# ESP32-C61 register map
Vendor: ESPRESSIF SYSTEMS (SHANGHAI) CO., LTD.; Series: ESP32 C-Series; File version: 1
CPU: RV32IMAC r0p0, little endian, no MPU, no FPU, 0 interrupt priority bits
Address unit: 32 bits
Registers are 32-bit, read-write, reset 0x0 unless marked. A register's access mark holds for its fields unless they carry their own. Offsets are from the block's base; [hi:lo] are bit positions; {n}, {i} and the like mark numbered series.

## INTERRUPT_CORE0 — Interrupt Controller (Core 0)
Base 0x60010000
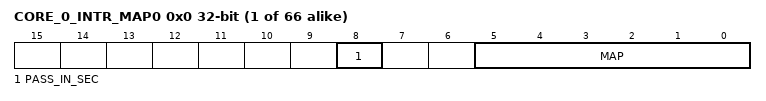
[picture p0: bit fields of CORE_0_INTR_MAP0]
{0x0+4i} CORE_0_INTR_MAP{i} (i=0..65)
  [8] PASS_IN_SEC, [5:0] MAP
{0x108+4i} CORE_0_INTR_STATUS{i} (i=0..2) ro — Represents the status of the interrupt sources. Each bit corresponds to one interrupt source
  [31:0] INT_STATUS_0 — Represents the status of the interrupt sources within interrupt-index-range 0 ~ 31. Each bit corresponds to one interrupt source 0:The corresponding interrupt source triggered an interrupt 1:No interrupt triggered
0x114 SRC_PASS_IN_SEC_STATUS_0 ro — PASS_IN_SEC status register for interrupt sources 0 ~ 31
  [31:0] INT_SRC_PASS_IN_SEC_STATUS_0 — Represents the PASS_IN_SEC status of the interrupt sources within interrupt-index-range 0 ~ 31. Each bit corresponds to one interrupt source 0:The corresponding interrupt source is not PASS_IN_SEC. 1:The corresponding interrupt source is PASS_IN_SEC.
0x118 SRC_PASS_IN_SEC_STATUS_1 ro — PASS_IN_SEC status register for interrupt sources 32 ~ 63
  [31:0] INT_SRC_PASS_IN_SEC_STATUS_1 — Represents the PASS_IN_SEC status of the interrupt sources within interrupt-index-range 32 ~ 63. Each bit corresponds to one interrupt source 0:The corresponding interrupt source is not PASS_IN_SEC. 1:The corresponding interrupt source is PASS_IN_SEC.
0x11C SRC_PASS_IN_SEC_STATUS_2 ro — PASS_IN_SEC status register for interrupt sources 64 ~ 65
  [1:0] INT_SRC_PASS_IN_SEC_STATUS_2 — Represents the PASS_IN_SEC status of the interrupt sources with interrupt-index-range 64 ~ 65. Each bit corresponds to one interrupt source 0:The corresponding interrupt source is not PASS_IN_SEC. 1:The corresponding interrupt source is PASS_IN_SEC.
0x120 SIG_IDX_ASSERT_IN_SEC — reserved
  [5:0] INT_SIG_IDX_ASSERT_IN_SEC
0x124 SECURE_STATUS ro — reserved
  [31:0] INT_SECURE_STATUS
0x128 CLOCK_GATE — Interrupt clock gating configure register
  [0] REG_CLK_EN
0x7FC INTERRUPT_DATE — Version control register

## INTPRI — INTPRI Peripheral
Base 0x600C5000
{0x90+4i} CPU_INTR_FROM_CPU{i} (i=0..3) — CPU_INTR_FROM_CPU{i} mapping register
  [0] CPU_INTR — CPU_INTR_FROM_CPU_%s mapping register.
0xA0 DATE — Version control register
0xA4 CLOCK_GATE reset 0x1 — register description
  [0] CLK_EN — Need add description
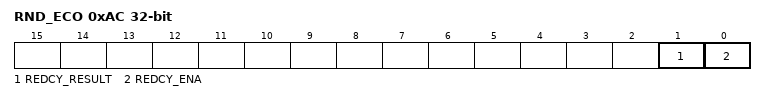
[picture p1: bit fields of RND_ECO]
0xAC RND_ECO access per field — redcy eco register.
  [1] REDCY_RESULT ro — Only reserved for ECO.
  [0] REDCY_ENA rw — Only reserved for ECO.
0xB0 RND_ECO_LOW — redcy eco low register.
  [31:0] REDCY_LOW — Only reserved for ECO.
0x3FC RND_ECO_HIGH reset 0xFFFFFFFF — redcy eco high register.
  [31:0] REDCY_HIGH — Only reserved for ECO.

## IO_MUX — Input/Output Multiplexer
Base 0x60090000
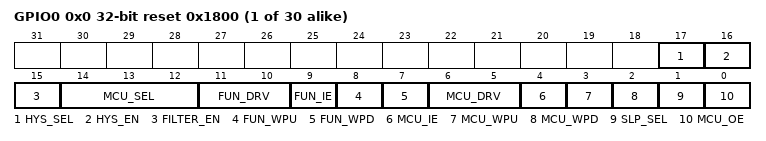
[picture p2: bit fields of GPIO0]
{0x0+4i} GPIO{i} (i=0..29) reset 0x1800 — IO_MUX Configure Registers for different pads
  [17] HYS_SEL — Select enabling signals of the pad from software and efuse hardware. 1: Select enabling siganl from slftware. 0: Select enabling signal from efuse hardware.
  [16] HYS_EN — Software enables hysteresis function for the pad. 1: Hysteresis enabled. 0: Hysteresis disabled.
  [15] FILTER_EN — Enable filter for pin input signals. 1: Filter enabled. 0: Filter disabled.
  [14:12] MCU_SEL — Select IO MUX function for this signal. 0: Select Function 1. 1: Select Function 2. etc.
  [11:10] FUN_DRV — Select the drive strength of the pad.
  [9] FUN_IE — Input enable of the pad. 1: input enabled. 0: input disabled.
  [8] FUN_WPU — Pull-up enable of the pad. 1: internal pull-up enabled. 0: internal pull-up disabled.
  [7] FUN_WPD — Pull-down enable of the pad. 1: internal pull-down enabled. 0: internal pull-down disabled.
  [6:5] MCU_DRV — Select the drive strength of the pad during sleep mode.
  [4] MCU_IE — Input enable of the pad during sleep mode. 1: input enabled. 0: input disabled.
  [3] MCU_WPU — Pull-up enable of the pad during sleep mode. 1: internal pull-up enabled. 0: internal pull-up disabled.
  [2] MCU_WPD — Pull-down enable of the pad in sleep mode. 1: internal pull-down enabled. 0: internal pull-down disabled.
  [1] SLP_SEL — Sleep mode selection of this pad. Set to 1 to put the pad in pad mode.
  [0] MCU_OE — Output enable of the pad in sleep mode. 1: output enabled. 0: output disabled.
0x1FC DATE — IO_MUX Version Control Register

## Notices in the file
Copyright 2025 Espressif Systems (Shanghai) PTE LTD
Licensed under the Apache License, Version 2.0 (the "License");
you may not use this file except in compliance with the License.
You may obtain a copy of the License at
http://www.apache.org/licenses/LICENSE-2.0
Unless required by applicable law or agreed to in writing, software
distributed under the License is distributed on an "AS IS" BASIS,
WITHOUT WARRANTIES OR CONDITIONS OF ANY KIND, either express or implied.
See the License for the specific language governing permissions and
limitations under the License.
